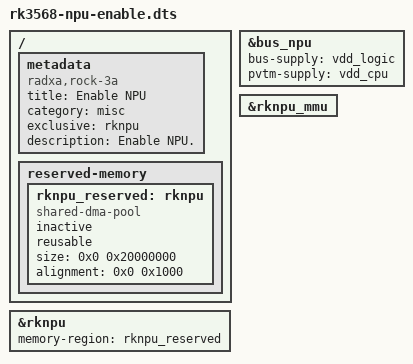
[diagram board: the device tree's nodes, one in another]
/dts-v1/;
/plugin/;

/ {
	metadata {
		title = "Enable NPU";
		compatible = "radxa,rock-3a", "radxa,rock-3b", "radxa,radxa-cm3-io", "radxa,e23", "radxa,e25";
		category = "misc";
		exclusive = "rknpu";
		description = "Enable NPU.";
	};

	fragment@0 {
		target = <&bus_npu>;

		__overlay__ {
			bus-supply = <&vdd_logic>;
			pvtm-supply = <&vdd_cpu>;
			status = "okay";
		};
	};

	fragment@1 {
		target = <&rknpu>;

		__overlay__ {
			memory-region = <&rknpu_reserved>;
			status = "okay";
		};
	};

	fragment@2 {
		target = <&rknpu_mmu>;

		__overlay__ {
			status = "okay";
		};
	};

	fragment@3 {
		target-path = "/";

		__overlay__ {
			reserved-memory {
				#address-cells = <2>;
				#size-cells = <2>;
				ranges;

				rknpu_reserved: rknpu {
					compatible = "shared-dma-pool";
					inactive;
					reusable;
					size = <0x0 0x20000000>;
					alignment = <0x0 0x1000>;
				};
			};
		};
	};
};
